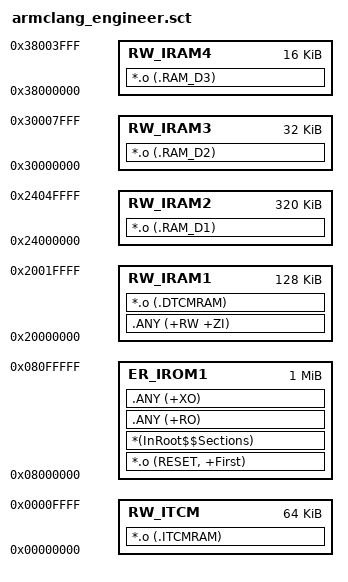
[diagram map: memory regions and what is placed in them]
; *************************************************************
; *** Scatter-Loading Description File generated by uVision ***
; *************************************************************

;LR_IROM1 0x08000000 0x00100000  {    ; load region size_region
;  ER_IROM1 0x08000000 0x00100000  {  ; load address = execution address
;   *.o (RESET, +First)
;   *(InRoot$$Sections)
;   .ANY (+RO)
;   .ANY (+XO)
;  }
;  RW_IRAM1 0x20000000 0x00020000  {  ; RW data
;   .ANY (+RW +ZI)
;  }
;  RW_IRAM2 0x24000000 0x00020000  {
;   .ANY (+RW +ZI)
;  }
;}

; *************************************************************
; *** Scatter-Loading Description File for STM32H723VGTx ***
; *************************************************************

LR_IROM1 0x08000000 0x00100000 {    ; FLASH region (1024KB)
    ER_IROM1 0x08000000 0x00100000 {
        *.o (RESET, +First)          ; Vector table first
        *(InRoot$$Sections)          ; Library sections
        .ANY (+RO)                   ; Read-only code and data
        .ANY (+XO)                   ; Execute-only code
    }

    ; DTCMRAM region (128KB)
    RW_IRAM1 0x20000000 0x00020000 {
        .ANY (+RW +ZI)               ; Read-write and zero-initialized data
		*.o (.DTCMRAM)
    }

    ; RAM_D1 region (320KB)
    RW_IRAM2 0x24000000 0x00050000 {
;        .ANY (+RW +ZI)
		*.o (.RAM_D1)
    }

    ; RAM_D2 region (32KB)
    RW_IRAM3 0x30000000 0x00008000 {
        *.o (.RAM_D2)
    }

    ; RAM_D3 region (16KB)
    RW_IRAM4 0x38000000 0x00004000 {
        *.o (.RAM_D3)
    }

    ; ITCMRAM region (64KB)
    RW_ITCM 0x00000000 0x00010000 {
        *.o (.ITCMRAM)
    }
}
